# STM32U3C5xx register map
File version: 1.0
Registers are 32-bit, read-write, reset 0x0 unless marked. A register's access mark holds for its fields unless they carry their own. Offsets are from the block's base; [hi:lo] are bit positions; {n}, {i} and the like mark numbered series.

## PKA
Base 0x420C2000
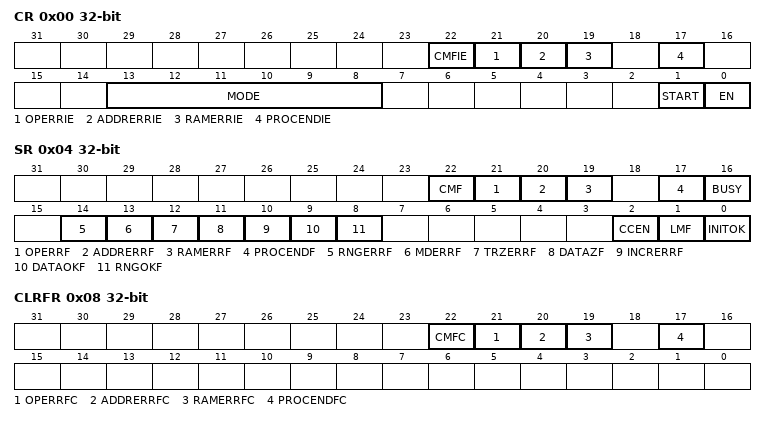
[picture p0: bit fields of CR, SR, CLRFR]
0x00 CR — PKA control register
  [22] CMFIE — Chaining mode flags interrupt enable
  [21] OPERRIE — Operation Error interrupt enable
  [20] ADDRERRIE — Address error interrupt enable
  [19] RAMERRIE — RAM error interrupt enable
  [17] PROCENDIE — End of operation interrupt enable
  [13:8] MODE — MODE[5:0] PKA operation code
  [1] START — Start operation
  [0] EN — PKA enable
0x04 SR — PKA status register
  [22] CMF — Chaining mode flag
  [21] OPERRF — PKA operation Error flag
  [20] ADDRERRF — Address error flag
  [19] RAMERRF — PKA RAM error flag
  [17] PROCENDF — PKA end of operation flag
  [16] BUSY — PKA operation is in progress
  [14] RNGERRF — PKA RNG error flag
  [13] MDERRF — PKA Mode error flag
  [12] TRZERRF — PKA Trailing zeros error flag
  [11] DATAZF — PKA Data zeroed error flag
  [10] INCRERRF — PKA Increment error flag
  [9] DATAOKF — PKA Data OK flag
  [8] RNGOKF — PKA RNG OK flag
  [2] CCEN — PKA Coupling and chaining mode enable
  [1] LMF — PKA Limited mode flag
  [0] INITOK — PKA initialisation flag
0x08 CLRFR — PKA clear flag register
  [22] CMFC — Clear chaining mode flag
  [21] OPERRFC — Clear PKA operation Error flag
  [20] ADDRERRFC — Clear address error flag
  [19] RAMERRFC — Clear PKA RAM error flag
  [17] PROCENDFC — Clear PKA end of operation flag
{0x400+4i} RAM[{i}] (i=0..1333)

## CCB — Coupling and chaining bridge (CCB)
Base 0x420C7C00
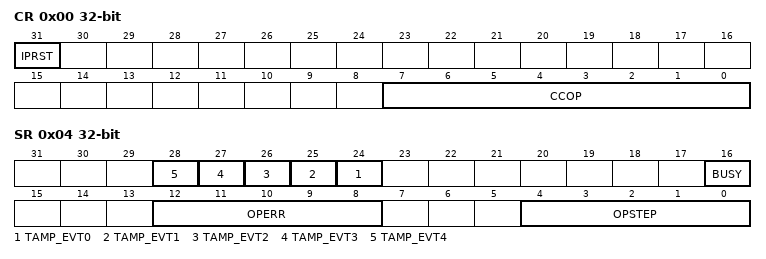
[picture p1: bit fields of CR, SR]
0x00 CR — CCB ccontrol register
  [31] IPRST — CCB reset
  [7:0] CCOP — Coupling and chaining operation
0x04 SR — CCB status register
  [n+24] TAMP_EVT{n} (n=0..4) — Tamper event {n} flag
  [16] BUSY — CCB busy
  [12:8] OPERR — Operation error
  [4:0] OPSTEP — Operation step
{0x10+4i} REFTAGR{i} (i=0..3) — CCB reference tag register

## DLYB_SDMMC1
Base 0x420C8400
Same registers: DLYB_OCTOSPI1 0x420CF000
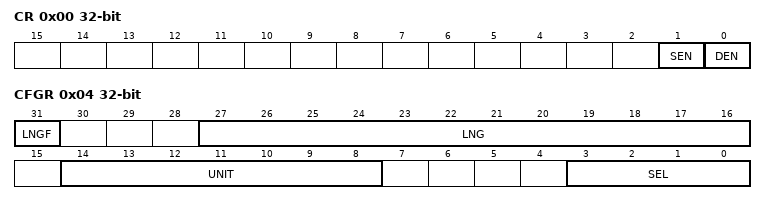
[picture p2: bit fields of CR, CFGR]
0x00 CR — Delay Block Control Register
  [1] SEN — Sampler length enable
  [0] DEN — Delay Block enable
0x04 CFGR — Delay Block Configuration Register
  [31] LNGF — Length valid flag
  [27:16] LNG — Delay line length value[11:0]
  [14:8] UNIT — Delay Defines the delay of a Unit delay cell[6:0]
  [3:0] SEL — Select the phase for the Output clock[3:0]

## DBGMCU — Debug MCU
Base 0xE0044000
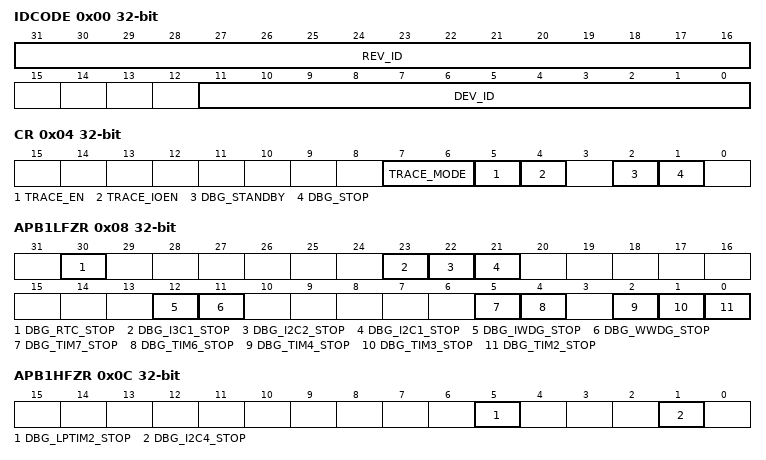
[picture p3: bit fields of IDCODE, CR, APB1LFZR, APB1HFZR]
0x00 IDCODE — MCU device ID code
  [31:16] REV_ID, [11:0] DEV_ID
0x04 CR — Debug MCU configuration register
  [7:6] TRACE_MODE, [5] TRACE_EN, [4] TRACE_IOEN, [2] DBG_STANDBY, [1] DBG_STOP
0x08 APB1LFZR — Debug MCU APB1L freeze register
  [30] DBG_RTC_STOP, [23] DBG_I3C1_STOP, [22] DBG_I2C2_STOP, [21] DBG_I2C1_STOP, [12] DBG_IWDG_STOP, [11] DBG_WWDG_STOP, [5] DBG_TIM7_STOP, [4] DBG_TIM6_STOP, [2] DBG_TIM4_STOP, [1] DBG_TIM3_STOP, [0] DBG_TIM2_STOP
0x0C APB1HFZR — Debug MCU APB1H freeze register
  [5] DBG_LPTIM2_STOP, [1] DBG_I2C4_STOP
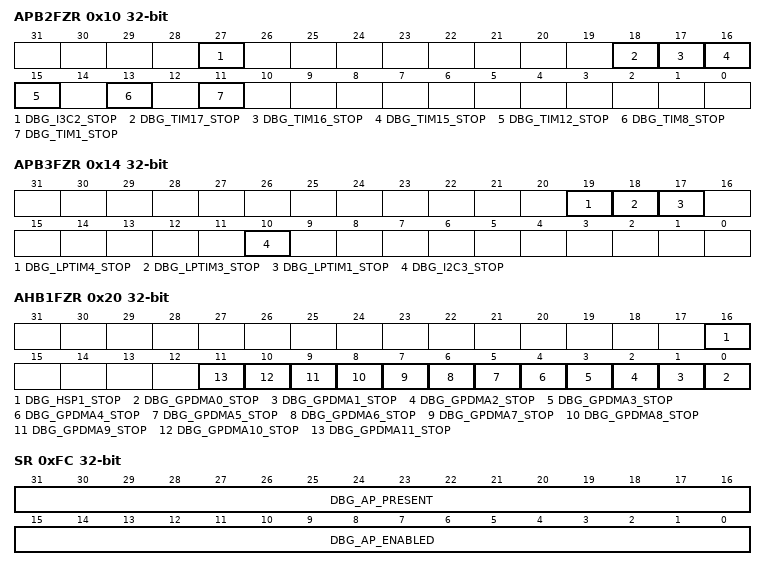
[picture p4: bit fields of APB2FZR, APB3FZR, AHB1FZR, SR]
0x10 APB2FZR — Debug MCU APB2 freeze register
  [27] DBG_I3C2_STOP, [18] DBG_TIM17_STOP, [17] DBG_TIM16_STOP, [16] DBG_TIM15_STOP, [15] DBG_TIM12_STOP, [13] DBG_TIM8_STOP, [11] DBG_TIM1_STOP
0x14 APB3FZR — Debug MCU APB3 freeze register
  [19] DBG_LPTIM4_STOP, [18] DBG_LPTIM3_STOP, [17] DBG_LPTIM1_STOP, [10] DBG_I2C3_STOP
0x20 AHB1FZR — Debug MCU AHB1 freeze register
  [16] DBG_HSP1_STOP, [n] DBG_GPDMA{n}_STOP (n=0..11)
0xFC SR — Debug MCU status register
  [31:16] DBG_AP_PRESENT, [15:0] DBG_AP_ENABLED
0x100 DGB_AUTH_HOST — Debug MCU debug host authentication register
0x104 DGB_AUTH_DEVICE — Debug MCU debug device authentication register
0xFD0 PIDR4 — Debug MCU CoreSight peripheral identity register 4
  [3:0] JEP106CON
0xFD4 PIDR0 — Debug MCU CoreSight peripheral identity register 0
  [7:0] PARTNUM
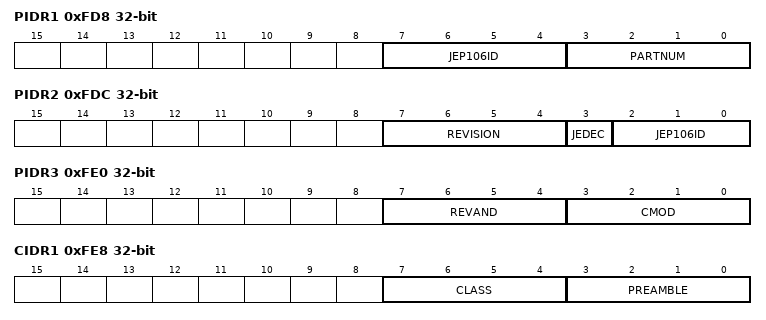
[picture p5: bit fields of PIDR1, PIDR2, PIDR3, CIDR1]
0xFD8 PIDR1 — Debug MCU CoreSight peripheral identity register 1
  [7:4] JEP106ID, [3:0] PARTNUM
0xFDC PIDR2 — Debug MCU CoreSight peripheral identity register 2
  [7:4] REVISION, [3] JEDEC, [2:0] JEP106ID
0xFE0 PIDR3 — Debug MCU CoreSight peripheral identity register 3
  [7:4] REVAND, [3:0] CMOD
0xFE4 CIDR0 — Debug MCU CoreSight component identity register 0
  [7:0] PREAMBLE
0xFE8 CIDR1 — Debug MCU CoreSight component identity register 1
  [7:4] CLASS, [3:0] PREAMBLE
0xFEC CIDR2 — Debug MCU CoreSight component identity register 2
  [7:0] PREAMBLE
0xFF0 CIDR3 — Debug MCU CoreSight component identity register 3
  [7:0] PREAMBLE
